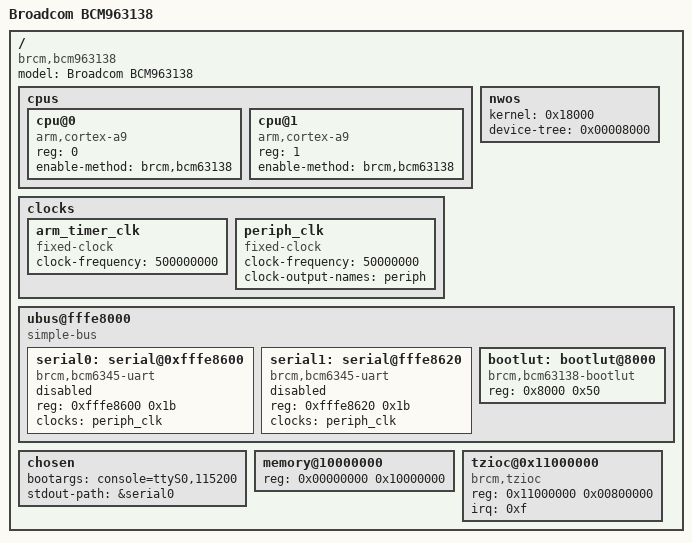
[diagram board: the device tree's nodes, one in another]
/*
 * Broadcom BCM63138 DTS
 */

/dts-v1/;
  
/ {
    compatible = "brcm,bcm63138";
    model = "Broadcom BcM63138 DSL SoC";

    cpus {
        #address-cells = <1>;
        #size-cells = <0>;

        cpu@0 {
            device_type = "cpu";
            compatible = "arm,cortex-a9";
            reg = <0>;
            enable-method = "brcm,bcm63138"; 
        };

        cpu@1 {
            device_type = "cpu";
            compatible = "arm,cortex-a9";
            reg = <1>;
            enable-method = "brcm,bcm63138"; 
        };
    };

    clocks {
        #address-cells = <1>;
        #size-cells = <0>;

        arm_timer_clk: arm_timer_clk {
            #clock-cells = <0>;
            compatible = "fixed-clock";
            clock-frequency = <500000000>; 
        };

        periph_clk: periph_clk { 
            #clock-cells = <0>;
            compatible = "fixed-clock";
            clock-frequency = <50000000>;
            clock-output-names = "periph";
        };
    };

    nwos {
        kernel = <0x18000>; /* this is the Linux entry point */
        device-tree = <0x00008000>;
    };

    /* Legacy UBUS base */
    ubus@fffe8000 {
        compatible = "simple-bus";
        #address-cells = <1>;
        #size-cells = <1>;
        ranges = <0 0xfffe8000 0x8100>;

        serial0: serial@0xfffe8600 {
            compatible = "brcm,bcm6345-uart","ns16550a";
            reg = <0xfffe8600 0x1b>;
            clocks = <&periph_clk>;
            clock-names = "periph";
            status = "disabled";
        };

        serial1: serial@fffe8620 {
            compatible = "brcm,bcm6345-uart","ns16550a";
            reg = <0xfffe8620 0x1b>;
            clocks = <&periph_clk>;
            clock-names = "periph";
            status = "disabled";
        };

        bootlut: bootlut@8000 { 
            compatible = "brcm,bcm63138-bootlut";
            reg = <0x8000 0x50>;
        };
    };
 };
 

/ {
    compatible = "brcm,bcm963138";
    model = "Broadcom BCM963138";
    #address-cells = <1>;
    #size-cells = <1>;

    chosen {
        bootargs = "console=ttyS0,115200";
        stdout-path = &serial0;
    };

    memory@10000000 {
        device_type = "memory";
        /* First  entry: ATF load address (not used)
           Second entry: OPTEE load address
         */
        reg = <0x00000000 0x10000000>;  
    };
    
	tzioc@0x11000000 {
		#address-cells = <0x1>;
		#size-cells = <0x1>;
		compatible = "brcm,tzioc";
		reg = <0x11000000 0x00800000>;
		irq = <0xf>;
	};

};
